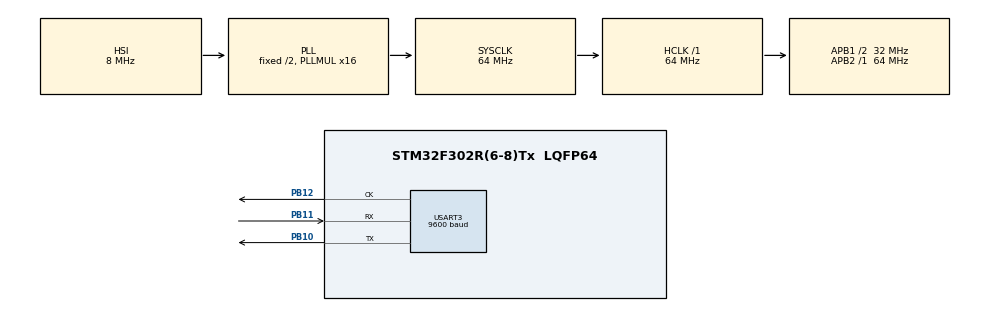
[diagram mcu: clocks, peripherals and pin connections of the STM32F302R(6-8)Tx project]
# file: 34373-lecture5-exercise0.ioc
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Mcu.Family=STM32F3
Mcu.Name=STM32F302R(6-8)Tx
Mcu.Package=LQFP64
NVIC.PriorityGroup=NVIC_PRIORITYGROUP_0
PB10.Mode=Synchronous
PB10.Signal=USART3_TX
PB11.Mode=Synchronous
PB11.Signal=USART3_RX
PB12.Mode=Synchronous
PB12.Signal=USART3_CK
PC14\ -\ OSC32_IN.Mode=LSE-External-Oscillator
PC14\ -\ OSC32_IN.Signal=RCC_OSC32_IN
PC15\ -\ OSC32_OUT.Mode=LSE-External-Oscillator
PC15\ -\ OSC32_OUT.Signal=RCC_OSC32_OUT
PF0-OSC_IN.Mode=HSE-External-Clock-Source
PF0-OSC_IN.Signal=RCC_OSC_IN
ProjectManager.HeapSize=0x200
ProjectManager.StackSize=0x400
ProjectManager.TargetToolchain=STM32CubeIDE
RCC.AHBFreq_Value=64000000
RCC.APB1CLKDivider=RCC_HCLK_DIV2
RCC.APB1Freq_Value=32000000
RCC.APB1TimFreq_Value=64000000
RCC.APB2Freq_Value=64000000
RCC.APB2TimFreq_Value=64000000
RCC.CortexFreq_Value=64000000
RCC.HCLKFreq_Value=64000000
RCC.HSE_VALUE=8000000
RCC.HSI_VALUE=8000000
RCC.PLLM=8
RCC.PLLMUL=RCC_PLL_MUL16
RCC.PLLN=336
RCC.PLLP=RCC_PLLP_DIV4
RCC.PLLQ=7
RCC.RCC_PLLsource_Clock_Source_FROM_HSE=RCC_HSE_PREDIV_DIV2
RCC.SYSCLKFreq_VALUE=64000000
RCC.SYSCLKSourceVirtual=RCC_SYSCLKSOURCE_PLLCLK
RCC.USBFreq_Value=64000000
USART3.BaudRate=9600
USART3.CLKPolarity=USART_POLARITY_LOW
USART3.Parity=PARITY_EVEN
USART3.VirtualMode-Synchronous=VM_SYNC
USART3.WordLength=WORDLENGTH_8B
board=NUCLEO-F302R8

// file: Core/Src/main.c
/* USER CODE BEGIN Header */
/**
  ******************************************************************************
  * @file           : main.c
  * @brief          : Main program body
  ******************************************************************************
  * @attention
  *
  * Copyright (c) 2026 STMicroelectronics.
  * All rights reserved.
  *
  * This software is licensed under terms that can be found in the LICENSE file
  * in the root directory of this software component.
  * If no LICENSE file comes with this software, it is provided AS-IS.
  *
  ******************************************************************************
  */
/* USER CODE END Header */
#include "main.h"
#include "usart.h"
#include "gpio.h"

/* USER CODE BEGIN Includes */
#include <stdio.h>
/* USER CODE END Includes */

/* USER CODE BEGIN PV */
double value = 1.0;
char buff[10];
/* USER CODE END PV */

void SystemClock_Config(void);

int main(void)
{

  /* MCU Configuration--------------------------------------------------------*/

  /* Reset of all peripherals, Initializes the Flash interface and the Systick. */
  HAL_Init();

  /* Configure the system clock */
  SystemClock_Config();

  /* Initialize all configured peripherals */
  MX_GPIO_Init();
  MX_USART3_Init();

  /* Infinite loop */
  while (1)
  {

    /* USER CODE BEGIN 3 */
	sprintf(buff, "%f\r\n", value);
	HAL_USART_Transmit(&husart3, (uint8_t *) buff, 10, 100);
	HAL_Delay(500);
	value = value + 0.01;
  }
  /* USER CODE END 3 */
}

void SystemClock_Config(void)
{
  RCC_OscInitTypeDef RCC_OscInitStruct = {0};
  RCC_ClkInitTypeDef RCC_ClkInitStruct = {0};

  /** Initializes the RCC Oscillators according to the specified parameters
  * in the RCC_OscInitTypeDef structure.
  */
  RCC_OscInitStruct.OscillatorType = RCC_OSCILLATORTYPE_HSI;
  RCC_OscInitStruct.HSIState = RCC_HSI_ON;
  RCC_OscInitStruct.HSICalibrationValue = RCC_HSICALIBRATION_DEFAULT;
  RCC_OscInitStruct.PLL.PLLState = RCC_PLL_ON;
  RCC_OscInitStruct.PLL.PLLSource = RCC_PLLSOURCE_HSI;
  RCC_OscInitStruct.PLL.PLLMUL = RCC_PLL_MUL16;
  if (HAL_RCC_OscConfig(&RCC_OscInitStruct) != HAL_OK)
  {
    Error_Handler();
  }

  /** Initializes the CPU, AHB and APB buses clocks
  */
  RCC_ClkInitStruct.ClockType = RCC_CLOCKTYPE_HCLK|RCC_CLOCKTYPE_SYSCLK
                              |RCC_CLOCKTYPE_PCLK1|RCC_CLOCKTYPE_PCLK2;
  RCC_ClkInitStruct.SYSCLKSource = RCC_SYSCLKSOURCE_PLLCLK;
  RCC_ClkInitStruct.AHBCLKDivider = RCC_SYSCLK_DIV1;
  RCC_ClkInitStruct.APB1CLKDivider = RCC_HCLK_DIV2;
  RCC_ClkInitStruct.APB2CLKDivider = RCC_HCLK_DIV1;

  if (HAL_RCC_ClockConfig(&RCC_ClkInitStruct, FLASH_LATENCY_2) != HAL_OK)
  {
    Error_Handler();
  }
}

void Error_Handler(void)
{
  __disable_irq();
  while (1)
  {
  }
}
